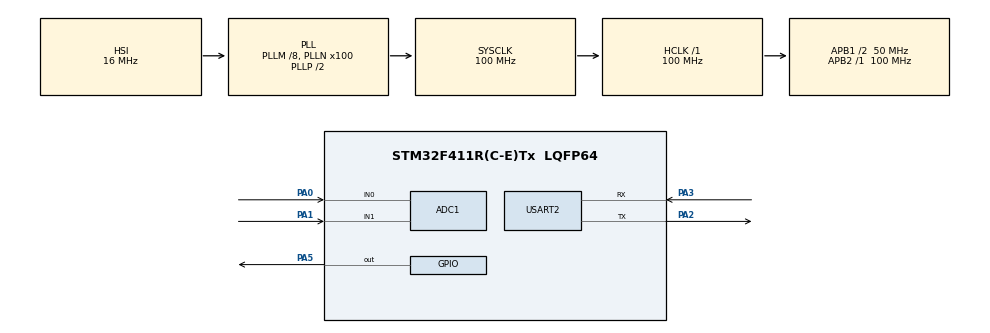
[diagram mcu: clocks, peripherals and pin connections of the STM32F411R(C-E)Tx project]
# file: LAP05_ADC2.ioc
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ADC1.Channel-4\#ChannelRegularConversion=ADC_CHANNEL_0
ADC1.Channel-5\#ChannelRegularConversion=ADC_CHANNEL_0
ADC1.Channel-6\#ChannelRegularConversion=ADC_CHANNEL_1
ADC1.Channel-7\#ChannelRegularConversion=ADC_CHANNEL_1
ADC1.ContinuousConvMode=ENABLE
ADC1.DMAContinuousRequests=ENABLE
ADC1.DiscontinuousConvMode=DISABLE
ADC1.NbrOfConversion=4
ADC1.NbrOfConversionFlag=1
ADC1.Rank-4\#ChannelRegularConversion=1
ADC1.Rank-5\#ChannelRegularConversion=2
ADC1.Rank-6\#ChannelRegularConversion=3
ADC1.Rank-7\#ChannelRegularConversion=4
ADC1.SamplingTime-4\#ChannelRegularConversion=ADC_SAMPLETIME_3CYCLES
ADC1.SamplingTime-5\#ChannelRegularConversion=ADC_SAMPLETIME_3CYCLES
ADC1.SamplingTime-6\#ChannelRegularConversion=ADC_SAMPLETIME_3CYCLES
ADC1.SamplingTime-7\#ChannelRegularConversion=ADC_SAMPLETIME_3CYCLES
ADC1.master=1
Dma.ADC1.0.Direction=DMA_PERIPH_TO_MEMORY
Dma.ADC1.0.FIFOMode=DMA_FIFOMODE_DISABLE
Dma.ADC1.0.Instance=DMA2_Stream0
Dma.ADC1.0.MemDataAlignment=DMA_MDATAALIGN_WORD
Dma.ADC1.0.MemInc=DMA_MINC_ENABLE
Dma.ADC1.0.Mode=DMA_CIRCULAR
Dma.ADC1.0.PeriphDataAlignment=DMA_PDATAALIGN_WORD
Dma.ADC1.0.PeriphInc=DMA_PINC_DISABLE
Dma.ADC1.0.Priority=DMA_PRIORITY_LOW
Dma.Request0=ADC1
Mcu.Family=STM32F4
Mcu.Name=STM32F411R(C-E)Tx
Mcu.Package=LQFP64
NVIC.DMA2_Stream0_IRQn=true\:0\:0\:false\:false\:true\:false\:true
NVIC.PriorityGroup=NVIC_PRIORITYGROUP_0
PA0-WKUP.Signal=ADCx_IN0
PA1.Signal=ADCx_IN1
PA2.Mode=Asynchronous
PA2.Signal=USART2_TX
PA3.Mode=Asynchronous
PA3.Signal=USART2_RX
PA5.Signal=GPIO_Output
ProjectManager.HeapSize=0x200
ProjectManager.StackSize=0x400
ProjectManager.TargetToolchain=MDK-ARM V5.27
RCC.48MHZClocksFreq_Value=50000000
RCC.AHBFreq_Value=100000000
RCC.APB1CLKDivider=RCC_HCLK_DIV2
RCC.APB1Freq_Value=50000000
RCC.APB1TimFreq_Value=100000000
RCC.APB2Freq_Value=100000000
RCC.APB2TimFreq_Value=100000000
RCC.CortexFreq_Value=100000000
RCC.FLatency-AdvancedSettings=FLASH_LATENCY_3
RCC.HCLKFreq_Value=100000000
RCC.HSE_VALUE=8000000
RCC.HSI_VALUE=16000000
RCC.LSE_VALUE=32768
RCC.PLLM=8
RCC.PLLN=100
RCC.SYSCLKFreq_VALUE=100000000
RCC.SYSCLKSource=RCC_SYSCLKSOURCE_PLLCLK
RCC.VCOOutputFreq_Value=200000000
SH.ADCx_IN0.0=ADC1_IN0,IN0
SH.ADCx_IN1.0=ADC1_IN1,IN1
USART2.VirtualMode=VM_ASYNC
board=NUCLEO-F411RE

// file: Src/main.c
/* USER CODE BEGIN Header */
/**
  ******************************************************************************
  * @file           : main.c
  * @brief          : Main program body
  ******************************************************************************
  * @attention
  *
  * <h2><center>&copy; Copyright (c) 2020 STMicroelectronics.
  * All rights reserved.</center></h2>
  *
  * This software component is licensed by ST under BSD 3-Clause license,
  * the "License"; You may not use this file except in compliance with the
  * License. You may obtain a copy of the License at:
  *                        opensource.org/licenses/BSD-3-Clause
  *
  ******************************************************************************
  */
/* USER CODE END Header */

#include "main.h"
#include "adc.h"
#include "dma.h"
#include "usart.h"
#include "gpio.h"

/* USER CODE BEGIN Includes */
#include "stdio.h"
#include "string.h"
/* USER CODE END Includes */

/* USER CODE BEGIN PV */
uint32_t adc_dma_val[4];
/* USER CODE END PV */

void SystemClock_Config(void);
/* USER CODE BEGIN PFP */
void displayHex(uint32_t);
/* USER CODE END PFP */

int main(void)
{

  /* MCU Configuration--------------------------------------------------------*/

  /* Reset of all peripherals, Initializes the Flash interface and the Systick. */
  HAL_Init();

  /* Configure the system clock */
  SystemClock_Config();

  /* Initialize all configured peripherals */
  MX_GPIO_Init();
  MX_DMA_Init();
  MX_ADC1_Init();
  MX_USART2_UART_Init();
  /* USER CODE BEGIN 2 */
	HAL_ADC_Start_DMA(&hadc1, adc_dma_val,4);
  /* USER CODE END 2 */

  /* Infinite loop */
  while (1)
  {

  }
}

void SystemClock_Config(void)
{
  RCC_OscInitTypeDef RCC_OscInitStruct = {0};
  RCC_ClkInitTypeDef RCC_ClkInitStruct = {0};

  /** Configure the main internal regulator output voltage
  */
  __HAL_RCC_PWR_CLK_ENABLE();
  __HAL_PWR_VOLTAGESCALING_CONFIG(PWR_REGULATOR_VOLTAGE_SCALE1);
  /** Initializes the CPU, AHB and APB busses clocks
  */
  RCC_OscInitStruct.OscillatorType = RCC_OSCILLATORTYPE_HSI;
  RCC_OscInitStruct.HSIState = RCC_HSI_ON;
  RCC_OscInitStruct.HSICalibrationValue = RCC_HSICALIBRATION_DEFAULT;
  RCC_OscInitStruct.PLL.PLLState = RCC_PLL_ON;
  RCC_OscInitStruct.PLL.PLLSource = RCC_PLLSOURCE_HSI;
  RCC_OscInitStruct.PLL.PLLM = 8;
  RCC_OscInitStruct.PLL.PLLN = 100;
  RCC_OscInitStruct.PLL.PLLP = RCC_PLLP_DIV2;
  RCC_OscInitStruct.PLL.PLLQ = 4;
  if (HAL_RCC_OscConfig(&RCC_OscInitStruct) != HAL_OK)
  {
    Error_Handler();
  }
  /** Initializes the CPU, AHB and APB busses clocks
  */
  RCC_ClkInitStruct.ClockType = RCC_CLOCKTYPE_HCLK|RCC_CLOCKTYPE_SYSCLK
                              |RCC_CLOCKTYPE_PCLK1|RCC_CLOCKTYPE_PCLK2;
  RCC_ClkInitStruct.SYSCLKSource = RCC_SYSCLKSOURCE_PLLCLK;
  RCC_ClkInitStruct.AHBCLKDivider = RCC_SYSCLK_DIV1;
  RCC_ClkInitStruct.APB1CLKDivider = RCC_HCLK_DIV2;
  RCC_ClkInitStruct.APB2CLKDivider = RCC_HCLK_DIV1;

  if (HAL_RCC_ClockConfig(&RCC_ClkInitStruct, FLASH_LATENCY_3) != HAL_OK)
  {
    Error_Handler();
  }
}

/* USER CODE BEGIN 4 */
void HAL_ADC_ConvHalfCpltCallback (ADC_HandleTypeDef * hadc)
{
	HAL_GPIO_WritePin(GPIOA, GPIO_PIN_5, GPIO_PIN_SET);
}
void HAL_ADC_ConvCpltCallback (ADC_HandleTypeDef * hadc)
{
	HAL_GPIO_WritePin(GPIOA, GPIO_PIN_5, GPIO_PIN_RESET);
}
/* USER CODE END 4 */

void Error_Handler(void)
{
}

/************************ (C) COPYRIGHT STMicroelectronics *****END OF FILE****/
